# PIC32MK1024MCF100 device description
Architecture: MIPS; Family: PIC32MK; Series: PIC32MK
Registers are 32-bit, read-write, no defined reset value unless marked. A register's access mark holds for its fields unless they carry their own. Offsets are from the block's base; [hi:lo] are bit positions; {n}, {i} and the like mark numbered series; 'fields as' and 'values as' point back to an identical list.

## MCPWM
Instances: MCPWM 0x1f82a000 in periph_pb2_std
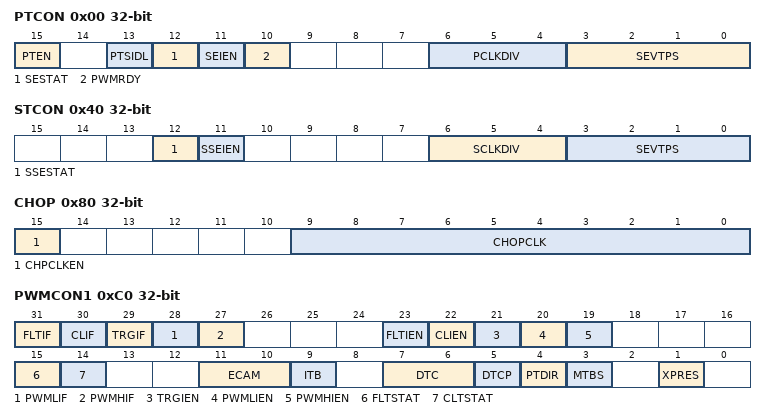
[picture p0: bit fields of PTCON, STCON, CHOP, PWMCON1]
0x00 PTCON — PWM Primary Time Base Control Register
  [15] PTEN — PWM Module Enable bit
    1=PWM module is enabled; 0=PWM module is disabled
  [13] PTSIDL — PWM Time Base Stop in Idle Mode bit
    1=PWM time base halts in CPU Idle mode; 0=PWM time base runs in CPU Idle mode
  [12] SESTAT — Special Event Interrupt Status bit
    1=Special Event Interrupt is pending; 0=Special Event Interrupt is not pending
  [11] SEIEN — Special Event Interrupt Enable bit
    1=Special Event Interrupt is enabled; 0=Special Event Interrupt is disabled
  [10] PWMRDY — PWM Module Status bit
    1=PWM module is ready and operation has begun; 0=PWM module is not ready
  [6:4] PCLKDIV — Primary PWM Input Clock Prescaler bits
    7=Divide by 128; 6=Divide by 64; 5=Divide by 32; 4=Divide by 16; 3=Divide by 8; 2=Divide by 4; 1=Divide by 2; 0=Divide by 1
  [3:0] SEVTPS — PWM Special Event Trigger Output Postscaler Select bits
    {v}=1:{v+1} postscaler generates Special Event trigger at every {v+1}th compare match event (v=3..15); 2=1:3 postscaler generates Special Event trigger at every 3rd compare match event; 1=1:2 postscaler generates Special Event trigger at every 2nd compare match event; 0=1:1 postscaler generates Special Event trigger at every compare match event
0x10 PTPER — Primary Master Time Base Period Register
  [15:0] PTPER
0x20 SEVTCMP — PWM Primary Special Event Compare Register
  [15:0] SEVTCMP
0x30 PMTMR — Primary Master Time Base Timer Register
  [15:0] PMTMR
0x40 STCON — Secondary Master Time Base Control Register
  [12] SSESTAT — Secondary Special Event Interrupt Status bit
    1=Secondary Special Event Interrupt is pending; 0=Secondary Special Event Interrupt is not pending
  [11] SSEIEN — Secondary Special Event Interrupt Enable bit
    1=Secondary Special Event Interrupt is enabled; 0=Secondary Special Event Interrupt is disabled
  [6:4] SCLKDIV — Secondary PWM Input Clock Prescaler
    values as PTCON.PCLKDIV
  [3:0] SEVTPS — PWM Secondary Special Event Trigger Output Postscaler Select bits
    values as PTCON.SEVTPS
0x50 STPER — Secondary Master Time Base Period Register
  [15:0] STPER
0x60 SSEVTCMP — PWM Secondary Special Event Compare Register
  [15:0] SSEVTCMP
0x70 SMTMR — Secondary Master Time Base Timer Register
  [15:0] SMTMR
0x80 CHOP — PWM Chop Clock Generator Register
  [15] CHPCLKEN — Enable Chop Clock Generator bit
    1=Chop clock generator is enabled; 0=Chop clock generator is disabled
  [9:0] CHOPCLK
0x90 PWMKEY — PWM Unlock Register
  [15:0] PWMKEY
0xC0 PWMCON1 — PWM Control Register x (x = 1 through 12)
  [31] FLTIF — Fault Interrupt Flag bit
    1=Fault interrupt has occurred; 0=Fault interrupt has not occurred
  [30] CLIF — Current-Limit Status bit
    1=Current limit has occurred; 0=Current limit has not occurred
  [29] TRGIF — Trigger Interrupt Status bit
    1=Trigger interrupt is pending; 0=Trigger interrupt is not pending
  [28] PWMLIF — PWML Interrupt Status bit
    1=PWM Timer equal to 0x0 interrupt has occurred; 0=PWM Interrupt has not occurred
  [27] PWMHIF — PWMH Interrupt Status bit
    1=PWM period match interrupt has occurred; 0=PWM period match interrupt has not occurred
  [23] FLTIEN — Fault Interrupt Enable bit
    1=Fault interrupt is enabled. If FLTIF is 1; 0=Fault interrupt is disabled
  [22] CLIEN — Current-Limit Interrupt Enable bit
    1=Current-limit interrupt is enabled. If CLIF is 1; 0=Current-limit interrupt is disabled
  [21] TRGIEN
  [20] PWMLIEN — PWM Low Phase Interrupt Enable bit
    1=When the PWM Timer is equal to 0x4; 0=PWM Period event interrupt request is disabled
  [19] PWMHIEN — PWM High Phase Interrupt Enable bit
    1=When the PWM Period matches the value in the PWM timer; 0=PWM Period event interrupt request is disabled
  [15] FLTSTAT — Fault Interrupt Status bit (This bit is cleared by setting FLTIEN to 0)
    1=Fault interrupt is pending; 0=No fault interrupt is pending
  [14] CLTSTAT — Current-Limit Interrupt Status bit (This bit is cleared by setting CLIEN to 0)
    1=Current-limit interrupt is pending; 0=No current-limit interrupt is pending
  [11:10] ECAM — Edge/Center-Aligned Mode Enable bits
    3=Asymmetric Center-Aligned mode with simultaneous update (PWM(min) Duty Cycle Resolution = (1/FSYSCLK)); 2=Asymmetric Center-Aligned mode double update (PWM(min) Duty Cycle Resolution = (1/FSYSCLK)); 1=Symmetric Center-Aligned mode (PWM(min) Duty Cycle Resolution = (2/FSYSCLK)); 0=Edge-Aligned mode (PWM(min) Duty Cycle Resolution = (1/FSYSCLK))
  [9] ITB — Independent Time Base Mode bit
    1=PHASEx registers provide time base period for this PWM generator; 0=PTPER/STPER register provides timing for this PWM generator based on the MTBS bit
  [7:6] DTC — Dead Time Control bits
    3=Dead Time Compensation mode enabled; 2=Dead time function is disabled; 1=Negative dead time actively applied for Complementary Output mode; 0=Positive dead time actively applied for all output modes
  [5] DTCP — Dead Time Compensation Polarity bit
    1=(If DTCMPx pin is 0)PWMxL is shortened; 0=(If DTCMPx pin is 0)PWMxH is shortened
  [4] PTDIR — PWM Timer Direction bit
    1=PWM timer is decrementing; 0=PWM timer is incrementing
  [3] MTBS — Master Time Base Select bit
    1=Secondary master time base is the clock source for the MCPWM module; 0=Primary master time base is the clock source for the MCPWM module
  [1] XPRES — External PWM Reset Control bit
    1=Current-limit source resets primary local time base for this PWM generator if it is in Independent Time Base mode and the PWM module enters the deassertion portion of the duty cycle; 0=External pins do not affect PWM time base
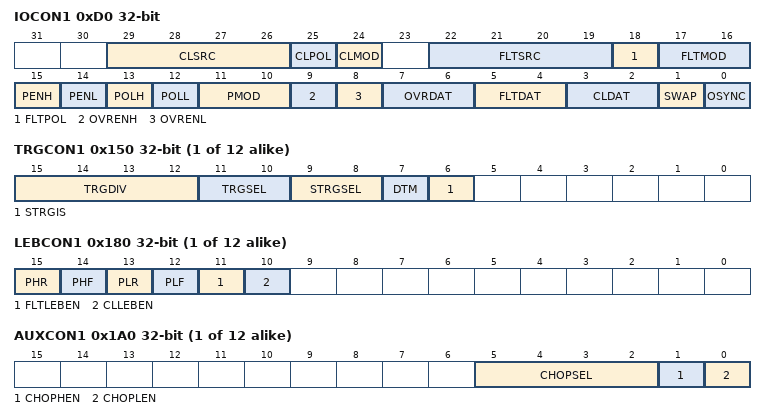
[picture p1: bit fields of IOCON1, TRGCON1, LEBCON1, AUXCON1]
0xD0 IOCON1 — PWMx I/O Control Register x (x = 1 through 12)
  [29:26] CLSRC — Current-Limit Control Signal Source select bit for PWM Generator x
    15=FLT15; {v}=Comparator {v-7} (v=8..12); {v}=FLT{v+1} (v=0..7)
  [25] CLPOL — Current-Limit Polarity bits for PWM Generator x
    1=The selected current-limit source is active-low; 0=The selected current-limit source is active-high
  [24] CLMOD — Current-Limit Mode Enable bit for PWM Generator x
    1=Current-limit function is enabled; 0=Current-limit function is disabled
  [22:19] FLTSRC — Fault Control Signal Source Select bits for PWM Generator x
    values as CLSRC
  [18] FLTPOL — Fault Polarity bits for PWM Generator x
    1=The selected fault source is active-low; 0=The selected fault source is active-high
  [17:16] FLTMOD — Fault Mode bits for PWM Generator x
    3=Fault input is disabled; 1=Selected fault source forces PWMxH, PWMxL pins to FLTDAT values (cycle by cycle); 0=Selected fault source forces PWMxH, PWMxL pins to FLTDAT values (Latched condition)
  [15] PENH — PWMxH Output Pin Ownership bit
    1=PWM module controls PWMxH pin; 0=GPIO module controls PWMxH pin
  [14] PENL — PWMxL Output Pin Ownership bit
    1=PWM module controls PWMxL pin; 0=GPIO module controls PWMxL pin
  [13] POLH — PWMxH Output Pin Polarity bit
    1=PWMxH pin is active-low; 0=PWMxH pin is active-high
  [12] POLL — PWMxL Output Pin Polarity bit
    1=PWMxL pin is active-low; 0=PWMxL pin is active-high
  [11:10] PMOD — PWM x I/O Pin Mode bits
    3=PWMxL output is held at logic 0 (adjusted by the POLL bit); 2=PWM I/O pin pair is in Push-Pull Output mode; 1=PWM I/O pin pair is in Redundant Output mode; 0=PWM I/O pin pair is in Complementary Output mode
  [9] OVRENH — Override Enable for PWMxH Pin bit
    1=OVRDAT provides data for output on PWMxH pin; 0=PWM generator provides data for PWMxH pin
  [8] OVRENL — Override Enable for PWMxL Pin bit
    1=OVRDAT provides data for output on PWMxL pin; 0=PWM generator provides data for PWMxL pin
  [7:6] OVRDAT — State for PWMxH
    If OVRENH=1; If OVRENL=1
  [5:4] FLTDAT
  [3:2] CLDAT
  [1] SWAP — SWAP PWMxH and PWMxL Pins bit
    1=PWMxH output signal is connected to PWMxL pin; PWMxL output signal is connected to PWMxH pin; 0=PWMxH and PWMxL output signals pins are mapped to their respective pins
  [0] OSYNC — Output Override Synchronization bit
    1=Output overrides through the OVRDAT bits are synchronized to the PWM time base; 0=Output overrides through the OVRDAT bits occur on next CPU clock boundary
0xE0 PDC1 — PWM Generator Duty Cycle Register x (x = 1 through 12)
  [15:0] PDC
0xF0 SDC1 — PWM Secondary Duty Cycle Register x (x = 1 through 12)
  [15:0] SDC
{0x0+0x100*i} PHASE{i} (i=1..12) — PWM Primary Phase Shift Register x (x = 1 through 12)
  [15:0] PHASE
{0x10+0x100*i} DTR{i} (i=1..12) — PWM Dead Time Register x (x = 1 through 12)
  [15:0] DTR
{0x20+0x100*i} ALTDTR{i} (i=1..12) — PWM Alternate Dead Time Register x (x = 1 through 12)
  [15:0] ALTDTR
{0x30+0x100*i} DTCOMP{i} (i=1..12) — Dead Time Compensation Register x (x = 1 through 12)
  [13:0] COMP
{0x40+0x100*i} TRIG{i} (i=1..12) — PWM Primary Trigger Compare Value Register x (x = 1 through 12)
  [15:0] TRGCMP
{0x50+0x100*i} TRGCON{i} (i=1..12) — PWM Trigger Control Register x (x = 1 through 12)
  [15:12] TRGDIV — Trigger x Output Divider bits
    {v}=Trigger output for every {v+1}th trigger event (v=3..15); 2=Trigger output for every 3rd trigger event; 1=Trigger output for every 2nd trigger event; 0=Trigger output for every trigger event
  [11:10] TRGSEL — Trigger Cycle Selection for Dual Cycle PWM Cycles
    2=When a trigger comparison match event occurs in the incrementing phase in the dual cycle PWM mode (PTDIR is 0); 1=When a trigger comparison match event occurs in the decrementing phase in the dual cycle PWM mode (PTDIR is 1); 0=When a trigger comparison match event occurs
  [9:8] STRGSEL — Secondary Trigger Cycle Selection bits for Dual Cycle PWM Cycles
    2=When a secondary PWM trigger comparison match event occurs in the second half of a dual cycle PWM mode (PTDIR is 0); 1=When a secondary PWM trigger comparison match event occurs in the first half of a dual cycle PWM mode (PTDIR is 1); 0=When a secondary PWM trigger comparison match event occurs
  [7] DTM — Dual ADC Trigger Mode
    1=Secondary trigger event is combined with the primary trigger event for purposes of creating a combined ADC trigger; 0=Secondary trigger event is not combined with the primary trigger event for purposes of creating a combined ADC trigger
  [6] STRGIS — Secondary Trigger Interrupt Select
    1=Selects the Secondary Trigger Register (STRIGx) based events for interrupts; 0=(When the DTM bit (TRGCONx) is clear (is 0)) TRIGx-based events for interrupts are selected / (When the DTM bit is set (= 1))the logical OR of both STRIGx and TRIGx based triggers for interrupts are selected
{0x60+0x100*i} STRIG{i} (i=1..12) — Secondary PWM Trigger Compare Register x (x = 1 through 12)
  [15:0] STRGCMP
{0x70+0x100*i} CAP{i} (i=1..12) — PWM Timer Capture Register x (x = 1 through 12)
  [15:0] CAP
{0x80+0x100*i} LEBCON{i} (i=1..12) — Leading-Edge Blanking Control Register x (x = 1 through 12)
  [15] PHR — PWMxH Rising Edge Trigger Enable bit
    1=Rising edge of PWMxH will trigger/retrigger the Leading-Edge Blanking counter; 0=Rising edge of PWMxH will not trigger/retrigger the Leading-Edge Blanking counter
  [14] PHF — PWMxH Falling Edge Trigger Enable bit
    1=Falling edge of PWMxH will trigger/retrigger the Leading-Edge Blanking counter; 0=Falling edge of PWMxH will not trigger/retrigger the Leading-Edge Blanking counter
  [13] PLR — PWMxL Rising Edge Trigger Enable bit
    1=Rising edge of PWMxL will trigger/retrigger the Leading-Edge Blanking counter; 0=Rising edge of PWMxL will not trigger/retrigger the Leading-Edge Blanking counter
  [12] PLF — PWMxL Falling Edge Trigger Enable bit
    1=Falling edge of PWMxL will trigger/retrigger the Leading-Edge Blanking counter; 0=Falling edge of PWMxL will not trigger/retrigger the Leading-Edge Blanking counter
  [11] FLTLEBEN — Fault Input Leading-Edge Blanking Enable bit
    1=Leading-Edge Blanking is applied to selected fault input; 0=Leading-Edge Blanking is not applied to selected fault input
  [10] CLLEBEN — Current-Limit Leading-Edge Blanking Enable bit
    1=Leading-Edge Blanking is applied to selected current-limit input; 0=Leading-Edge Blanking is not applied to selected current-limit input
{0x90+0x100*i} LEBDLY{i} (i=1..12) — Leading-Edge Blanking Delay Register x (x = 1 through 12)
  [11:0] LEB
{0xA0+0x100*i} AUXCON{i} (i=1..12) — PWM Auxiliary Control Register x (x = 1 through 12)
  [5:2] CHOPSEL — PWM Chop Clock Source Select bits
    15=Reserved. Do not use; 14=Reserved. Do not use; 13=Reserved. Do not use; 12=PWM12H selected as CHOP clock source; 7=PWM7H selected as CHOP clock source; 1=PWM1H selected as CHOP clock source; 0=Chop clock generator selected as CHOP clock source
  [1] CHOPHEN — PWMxH Output Chopping Enable bit
    1=PWMxH chopping function is enabled; 0=PWMxH chopping function is disabled
  [0] CHOPLEN — PWMxL Output Chopping Enable bit
    1=PWMxL chopping function is enabled; 0=PWMxL chopping function is disabled
{0xB0+0x100*i} PTMR{i} (i=1..12) — PWM Timer Register x (x = 1 through 12)
  [15:0] TMR
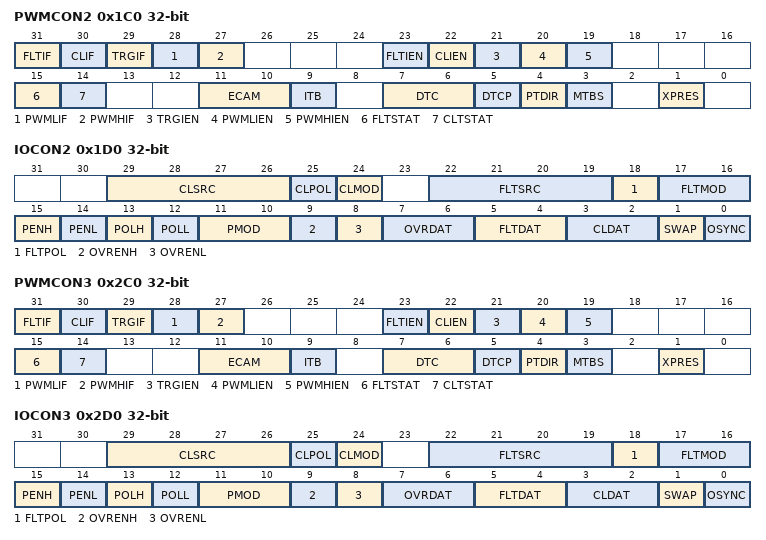
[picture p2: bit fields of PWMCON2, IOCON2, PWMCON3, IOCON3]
0x1C0 PWMCON2 — PWM Control Register x (x = 1 through 12)
  fields as PWMCON1
0x1D0 IOCON2 — PWMx I/O Control Register x (x = 1 through 12)
  fields as IOCON1
0x1E0 PDC2 — PWM Generator Duty Cycle Register x (x = 1 through 12)
  [15:0] PDC
0x1F0 SDC2 — PWM Secondary Duty Cycle Register x (x = 1 through 12)
  [15:0] SDC
0x2C0 PWMCON3 — PWM Control Register x (x = 1 through 12)
  fields as PWMCON1
0x2D0 IOCON3 — PWMx I/O Control Register x (x = 1 through 12)
  fields as IOCON1
0x2E0 PDC3 — PWM Generator Duty Cycle Register x (x = 1 through 12)
  [15:0] PDC
0x2F0 SDC3 — PWM Secondary Duty Cycle Register x (x = 1 through 12)
  [15:0] SDC
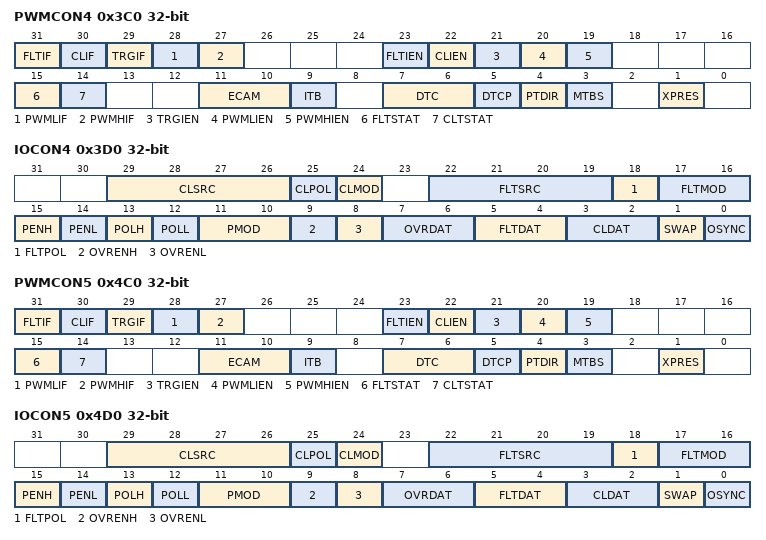
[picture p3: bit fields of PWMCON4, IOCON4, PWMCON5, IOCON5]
0x3C0 PWMCON4 — PWM Control Register x (x = 1 through 12)
  fields as PWMCON1
0x3D0 IOCON4 — PWMx I/O Control Register x (x = 1 through 12)
  fields as IOCON1
0x3E0 PDC4 — PWM Generator Duty Cycle Register x (x = 1 through 12)
  [15:0] PDC
0x3F0 SDC4 — PWM Secondary Duty Cycle Register x (x = 1 through 12)
  [15:0] SDC
0x4C0 PWMCON5 — PWM Control Register x (x = 1 through 12)
  fields as PWMCON1
0x4D0 IOCON5 — PWMx I/O Control Register x (x = 1 through 12)
  fields as IOCON1
0x4E0 PDC5 — PWM Generator Duty Cycle Register x (x = 1 through 12)
  [15:0] PDC
0x4F0 SDC5 — PWM Secondary Duty Cycle Register x (x = 1 through 12)
  [15:0] SDC
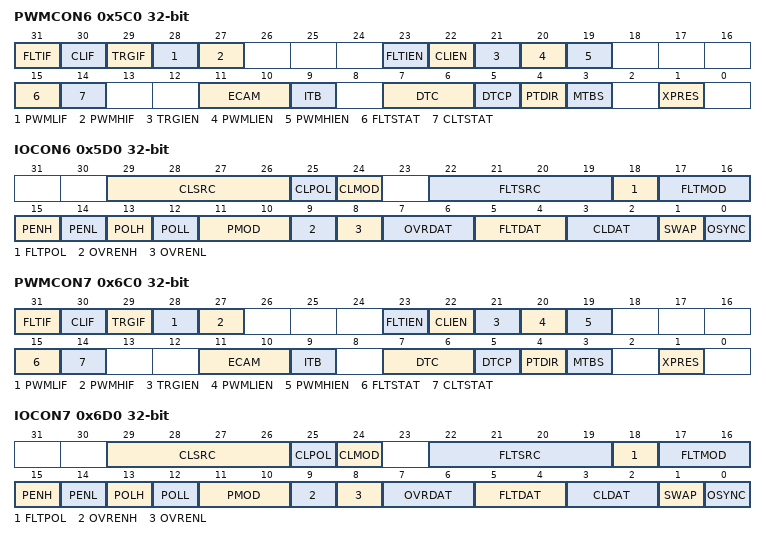
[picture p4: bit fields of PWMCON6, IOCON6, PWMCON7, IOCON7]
0x5C0 PWMCON6 — PWM Control Register x (x = 1 through 12)
  fields as PWMCON1
0x5D0 IOCON6 — PWMx I/O Control Register x (x = 1 through 12)
  fields as IOCON1
0x5E0 PDC6 — PWM Generator Duty Cycle Register x (x = 1 through 12)
  [15:0] PDC
0x5F0 SDC6 — PWM Secondary Duty Cycle Register x (x = 1 through 12)
  [15:0] SDC
0x6C0 PWMCON7 — PWM Control Register x (x = 1 through 12)
  fields as PWMCON1
0x6D0 IOCON7 — PWMx I/O Control Register x (x = 1 through 12)
  fields as IOCON1
0x6E0 PDC7 — PWM Generator Duty Cycle Register x (x = 1 through 12)
  [15:0] PDC
0x6F0 SDC7 — PWM Secondary Duty Cycle Register x (x = 1 through 12)
  [15:0] SDC
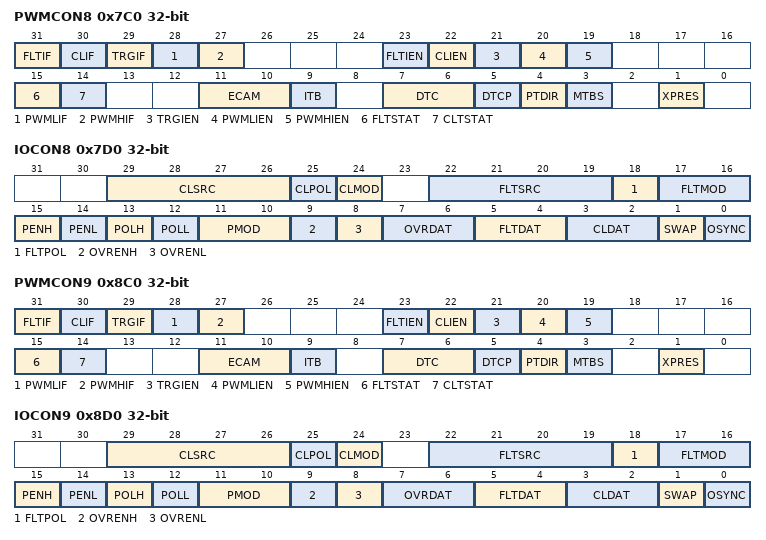
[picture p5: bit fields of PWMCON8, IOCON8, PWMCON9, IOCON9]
0x7C0 PWMCON8 — PWM Control Register x (x = 1 through 12)
  fields as PWMCON1
0x7D0 IOCON8 — PWMx I/O Control Register x (x = 1 through 12)
  fields as IOCON1
0x7E0 PDC8 — PWM Generator Duty Cycle Register x (x = 1 through 12)
  [15:0] PDC
0x7F0 SDC8 — PWM Secondary Duty Cycle Register x (x = 1 through 12)
  [15:0] SDC
0x8C0 PWMCON9 — PWM Control Register x (x = 1 through 12)
  fields as PWMCON1
0x8D0 IOCON9 — PWMx I/O Control Register x (x = 1 through 12)
  fields as IOCON1
0x8E0 PDC9 — PWM Generator Duty Cycle Register x (x = 1 through 12)
  [15:0] PDC
0x8F0 SDC9 — PWM Secondary Duty Cycle Register x (x = 1 through 12)
  [15:0] SDC
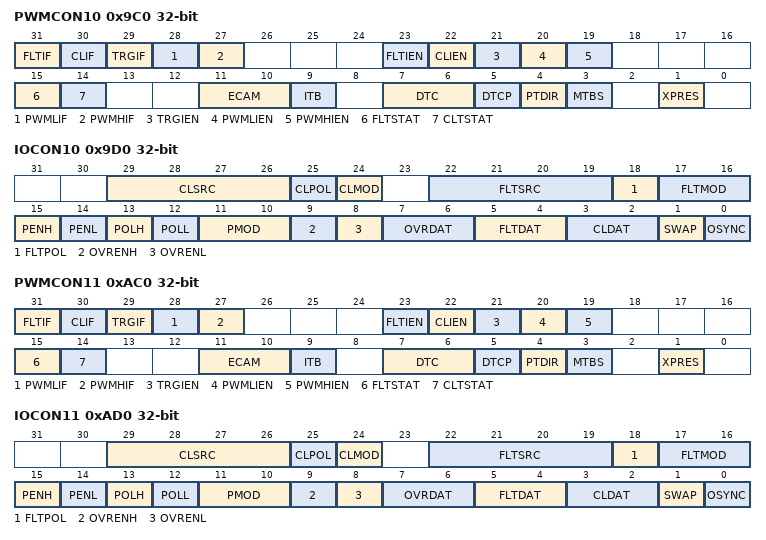
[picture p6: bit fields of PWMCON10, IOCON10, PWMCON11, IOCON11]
0x9C0 PWMCON10 — PWM Control Register x (x = 1 through 12)
  fields as PWMCON1
0x9D0 IOCON10 — PWMx I/O Control Register x (x = 1 through 12)
  fields as IOCON1
0x9E0 PDC10 — PWM Generator Duty Cycle Register x (x = 1 through 12)
  [15:0] PDC
0x9F0 SDC10 — PWM Secondary Duty Cycle Register x (x = 1 through 12)
  [15:0] SDC
0xAC0 PWMCON11 — PWM Control Register x (x = 1 through 12)
  fields as PWMCON1
0xAD0 IOCON11 — PWMx I/O Control Register x (x = 1 through 12)
  fields as IOCON1
0xAE0 PDC11 — PWM Generator Duty Cycle Register x (x = 1 through 12)
  [15:0] PDC
0xAF0 SDC11 — PWM Secondary Duty Cycle Register x (x = 1 through 12)
  [15:0] SDC
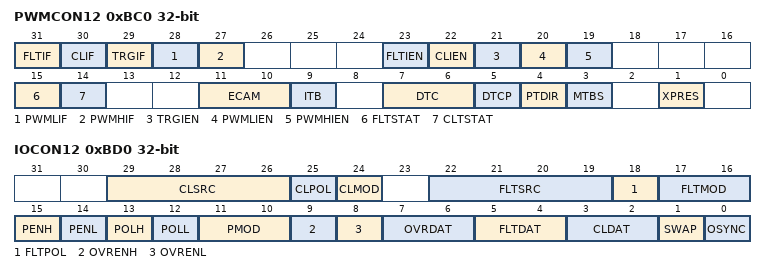
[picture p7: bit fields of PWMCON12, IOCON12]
0xBC0 PWMCON12 — PWM Control Register x (x = 1 through 12)
  fields as PWMCON1
0xBD0 IOCON12 — PWMx I/O Control Register x (x = 1 through 12)
  fields as IOCON1
0xBE0 PDC12 — PWM Generator Duty Cycle Register x (x = 1 through 12)
  [15:0] PDC
0xBF0 SDC12 — PWM Secondary Duty Cycle Register x (x = 1 through 12)
  [15:0] SDC

## Notices in the file
Copyright (c) 2017 Microchip Technology Inc.
SPDX-License-Identifier: Apache-2.0
Licensed under the Apache License, Version 2.0 (the "License");
you may not use this file except in compliance with the License.
You may obtain a copy of the License at
http://www.apache.org/licenses/LICENSE-2.0
Unless required by applicable law or agreed to in writing, software
distributed under the License is distributed on an "AS IS" BASIS,
WITHOUT WARRANTIES OR CONDITIONS OF ANY KIND, either express or implied.
See the License for the specific language governing permissions and
limitations under the License.
